VERSION ""

NS_ :

BS_:

BU_: ACC_Sys_Variables EnginControl InstrumentCluster BrakeControl ACC

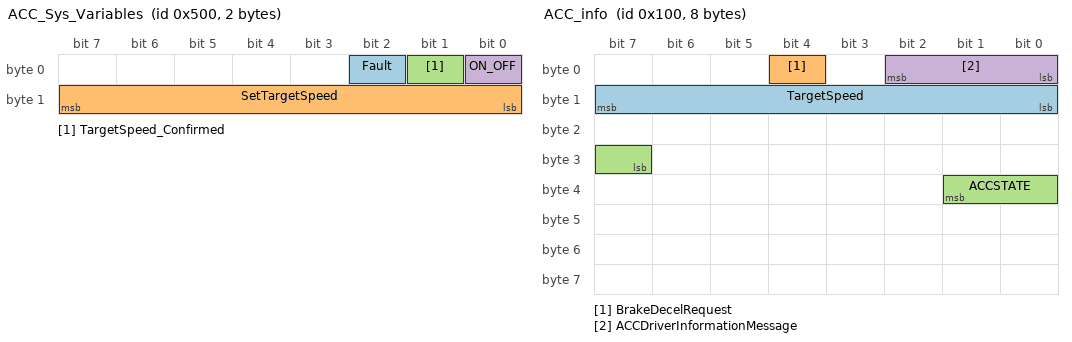
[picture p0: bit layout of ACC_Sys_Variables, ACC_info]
BO_ 1280 ACC_Sys_Variables: 2 ACC_Sys_Variables
 SG_ Fault : 2|1@1+ (1,0) [0|1] "" Vector__XXX
 SG_ SetTargetSpeed : 8|8@1+ (1,0) [0|255] "" Vector__XXX
 SG_ TargetSpeed_Confirmed : 1|1@1+ (1,0) [0|1] "0" Vector__XXX
 SG_ ON_OFF : 0|1@1+ (1,0) [0|1] ""  BrakeControl,EnginControl,InstrumentCluster,ACC

BO_ 1024 ECM_inf: 8 EnginControl
 SG_ BrakeSwitch2 : 0|1@1+ (1,0) [0|1] ""  ACC

BO_ 768 BCM_info: 8 BrakeControl
 SG_ VehicleSpeed : 0|8@1+ (1,0) [0|255] ""  ACC,EnginControl

BO_ 256 ACC_info: 8 ACC
 SG_ TargetSpeed : 8|8@1+ (1,0) [0|255] ""  EnginControl
 SG_ BrakeDecelRequest : 4|1@1+ (1,0) [0|1] ""  BrakeControl
 SG_ ACCSTATE : 31|3@1+ (1,0) [0|7] ""  EnginControl,BrakeControl
 SG_ ACCDriverInformationMessage : 0|3@1+ (1,0) [0|7] ""  InstrumentCluster

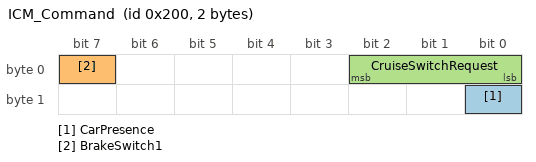
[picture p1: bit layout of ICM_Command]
BO_ 512 ICM_Command: 2 InstrumentCluster
 SG_ CarPresence : 8|1@1+ (1,0) [0|1] ""  ACC,BrakeControl
 SG_ BrakeSwitch1 : 7|1@1+ (1,0) [0|1] ""  ACC
 SG_ CruiseSwitchRequest : 0|3@1+ (1,0) [0|7] ""  ACC

BA_DEF_ BO_  "GenMsgDLC" INT 0 8;
BA_DEF_  "NmAsrCanMsgCycleTime" INT 0 0;
BA_DEF_  "NmAsrBaseAddress" HEX 0 536870911;
BA_DEF_ SG_  "NWM_WakeupAllowed" ENUM  "Yes","No";
BA_DEF_ BO_  "GenMsgStartDelayTime" INT 0 500;
BA_DEF_ SG_  "GenSigSendType" ENUM  "Cyclic","Event-based";
BA_DEF_ BO_  "GenMsgSendType" ENUM  "Cyclic","Event-based";
BA_DEF_ BO_  "GenMsgILSupport" ENUM  "Yes","No";
BA_DEF_ BO_  "GenMsgCycleTimeFast" INT 0 100;
BA_DEF_ BO_  "GenMsgCycleTime" INT 0 50000;
BA_DEF_ SG_  "GenSigStartValue" FLOAT 0 1000000000;
BA_DEF_  "BusType" STRING ;
BA_DEF_DEF_  "GenMsgDLC" 8;
BA_DEF_DEF_  "NmAsrCanMsgCycleTime" 640;
BA_DEF_DEF_  "NmAsrBaseAddress" 1280;
BA_DEF_DEF_  "NWM_WakeupAllowed" "Yes";
BA_DEF_DEF_  "GenMsgStartDelayTime" 0;
BA_DEF_DEF_  "GenSigSendType" "Cyclic";
BA_DEF_DEF_  "GenMsgSendType" "Cyclic";
BA_DEF_DEF_  "GenMsgILSupport" "Yes";
BA_DEF_DEF_  "GenMsgCycleTimeFast" 10;
BA_DEF_DEF_  "GenMsgCycleTime" 100;
BA_DEF_DEF_  "GenSigStartValue" 0;
BA_DEF_DEF_  "BusType" "CAN";
BA_ "GenMsgCycleTime" BO_ 1024 75;
BA_ "GenMsgStartDelayTime" BO_ 1024 23;
BA_ "GenMsgCycleTime" BO_ 768 50;
BA_ "GenMsgStartDelayTime" BO_ 768 25;
BA_ "GenMsgStartDelayTime" BO_ 256 34;
BA_ "GenMsgCycleTime" BO_ 512 120;
BA_ "GenMsgStartDelayTime" BO_ 512 15;
BA_ "GenSigStartValue" SG_ 1280 SetTargetSpeed 30;
VAL_ 1280 Fault 1 "Fault_detected" 0 "Fault_Notdetected" ;
VAL_ 1280 TargetSpeed_Confirmed 1 "T_Confirmed" 0 "T_NotConfirmed" ;
VAL_ 1280 ON_OFF 1 "On" 0 "OFF" ;
VAL_ 1024 BrakeSwitch2 1 "AppliedBrakeSwitch" 0 "NotAppliedBrakeSwitch" ;
VAL_ 256 BrakeDecelRequest 1 "Apply" 0 "DoNotApply" ;
VAL_ 256 ACCSTATE 5 "Fault" 4 "DriverInterventionRequired" 3 "Standby" 2 "Active" 0 "OFF" ;
VAL_ 256 ACCDriverInformationMessage 5 "Fault" 4 "DriverInterventionRequired" 3 "Standby" 2 "Active" 1 "On" 0 "OFF" ;
VAL_ 512 CarPresence 1 "Present" 0 "NotPresent" ;
VAL_ 512 BrakeSwitch1 1 "AppliedBrakeSwitch" 0 "NotAppliedBrakeSwitch" ;
VAL_ 512 CruiseSwitchRequest 6 "TimeGapM" 5 "TimeGapP" 4 "Resume" 3 "Coast" 2 "SetAccel" 1 "ON" 0 "OFF" ;
